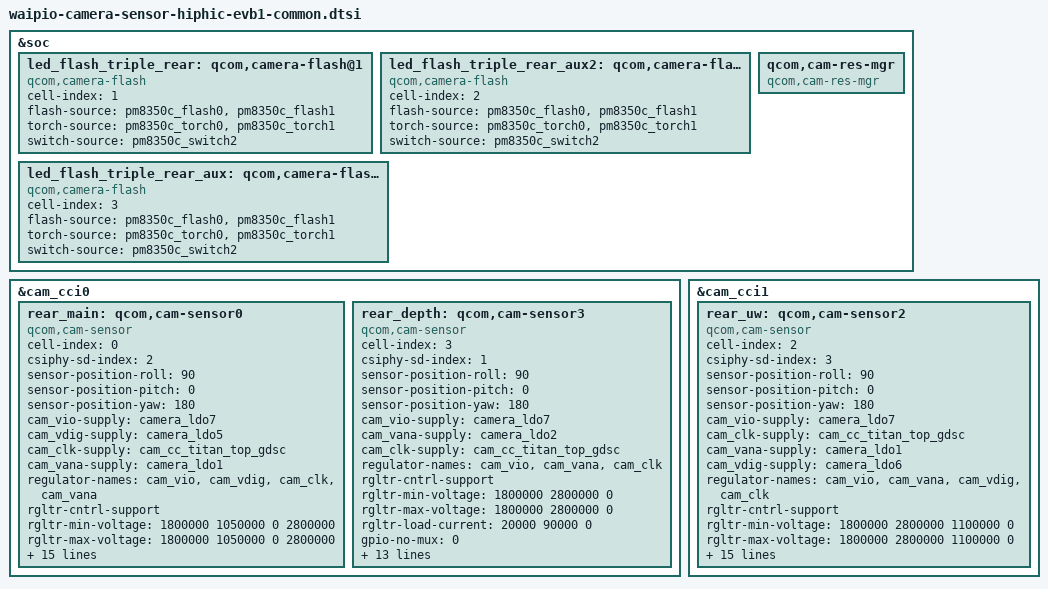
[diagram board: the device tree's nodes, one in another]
/*
   This base is original from "waipio-camera-sensor-mtp.dtsi"
*/
#include <dt-bindings/clock/qcom,camcc-waipio.h>

&soc {
	led_flash_triple_rear: qcom,camera-flash@1 {
		cell-index = <1>;
		compatible = "qcom,camera-flash";
		flash-source = <&pm8350c_flash0 &pm8350c_flash1>;
		torch-source = <&pm8350c_torch0 &pm8350c_torch1>;
		switch-source = <&pm8350c_switch2>;
		status = "ok";
	};

	led_flash_triple_rear_aux2: qcom,camera-flash@2 {
		cell-index = <2>;
		compatible = "qcom,camera-flash";
		flash-source = <&pm8350c_flash0 &pm8350c_flash1>;
		torch-source = <&pm8350c_torch0 &pm8350c_torch1>;
		switch-source = <&pm8350c_switch2>;
		status = "ok";
	};

	led_flash_triple_rear_aux: qcom,camera-flash@3 {
		cell-index = <3>;
		compatible = "qcom,camera-flash";
		flash-source = <&pm8350c_flash0 &pm8350c_flash1>;
		torch-source = <&pm8350c_torch0 &pm8350c_torch1>;
		switch-source = <&pm8350c_switch2>;
		status = "ok";
	};

	qcom,cam-res-mgr {
		compatible = "qcom,cam-res-mgr";
		status = "ok";
	};
};

&cam_cci0 {

	rear_main: qcom,cam-sensor0 {
		cell-index = <0>;
		compatible = "qcom,cam-sensor";
		csiphy-sd-index = <2>;
		sensor-position-roll = <90>;
		sensor-position-pitch = <0>;
		sensor-position-yaw = <180>;
		cam_vio-supply = <&camera_ldo7>;
		cam_vdig-supply = <&camera_ldo5>;
		cam_clk-supply = <&cam_cc_titan_top_gdsc>;
		cam_vana-supply = <&camera_ldo1>;
		regulator-names = "cam_vio", "cam_vdig",
			"cam_clk", "cam_vana";
		rgltr-cntrl-support;
		rgltr-min-voltage = <1800000 1050000 0 2800000>;
		rgltr-max-voltage = <1800000 1050000 0 2800000>;
		rgltr-load-current = <155000 680000 0 50000>;
		gpio-no-mux = <0>;
		pinctrl-names = "cam_default", "cam_suspend";
		pinctrl-0 = <&cam_sensor_mclk2_active
			&cam_sensor_active_rst2>;
		pinctrl-1 = <&cam_sensor_mclk2_suspend
			&cam_sensor_suspend_rst2>;
		gpios = <&tlmm 102 0>,
			<&tlmm 117 0>;
		gpio-reset = <1>;
		gpio-req-tbl-num = <0 1>;
		gpio-req-tbl-flags = <1 0>;
		gpio-req-tbl-label = "CAMIF_MCLK2",
					"CAM_RESET2";
		cci-master = <0>;
		clocks = <&clock_camcc CAM_CC_MCLK2_CLK>;
		clock-names = "cam_clk";
		clock-cntl-level = "nominal";
		clock-rates = <24000000>;
		status = "ok";
	};

	rear_depth: qcom,cam-sensor3 {
		cell-index = <3>;
		compatible = "qcom,cam-sensor";
		csiphy-sd-index = <1>;
		sensor-position-roll = <90>;
		sensor-position-pitch = <0>;
		sensor-position-yaw = <180>;
		cam_vio-supply = <&camera_ldo7>;
		cam_vana-supply = <&camera_ldo2>;
		cam_clk-supply = <&cam_cc_titan_top_gdsc>;
		regulator-names = "cam_vio", "cam_vana", "cam_clk";
		rgltr-cntrl-support;
		rgltr-min-voltage = <1800000 2800000 0>;
		rgltr-max-voltage = <1800000 2800000 0>;
		rgltr-load-current = <20000 90000 0>;
		gpio-no-mux = <0>;
		pinctrl-names = "cam_default", "cam_suspend";
		pinctrl-0 = <&cam_sensor_mclk1_active
				 &cam_sensor_active_rst1>;
		pinctrl-1 = <&cam_sensor_mclk1_suspend
				 &cam_sensor_suspend_rst1>;
		gpios = <&tlmm 101 0>,
			<&tlmm 24 0>;
		gpio-reset = <1>;
		gpio-req-tbl-num = <0 1>;
		gpio-req-tbl-flags = <1 0>;
		gpio-req-tbl-label = "CAMIF_MCLK1",
					"CAM_RESET1";
		cci-master = <1>;
		clocks = <&clock_camcc CAM_CC_MCLK1_CLK>;
		clock-names = "cam_clk";
		clock-cntl-level = "nominal";
		clock-rates = <24000000>;
		status = "ok";
	};
};

&cam_cci1 {
	rear_uw: qcom,cam-sensor2 {
		cell-index = <2>;
		compatible = "qcom,cam-sensor";
		csiphy-sd-index = <3>;
		sensor-position-roll = <90>;
		sensor-position-pitch = <0>;
		sensor-position-yaw = <180>;
		cam_vio-supply = <&camera_ldo7>;
		cam_clk-supply = <&cam_cc_titan_top_gdsc>;
		cam_vana-supply = <&camera_ldo1>;
		cam_vdig-supply = <&camera_ldo6>;
		regulator-names = "cam_vio", "cam_vana",
			"cam_vdig", "cam_clk";
		rgltr-cntrl-support;
		rgltr-min-voltage = <1800000 2800000 1100000 0>;
		rgltr-max-voltage = <1800000 2800000 1100000 0>;
		rgltr-load-current = <128000 128000 50000 0>;
		gpio-no-mux = <0>;
		pinctrl-names = "cam_default", "cam_suspend";
		pinctrl-0 = <&cam_sensor_mclk3_active
			&cam_sensor_active_rst3>;
		pinctrl-1 = <&cam_sensor_mclk3_suspend
			&cam_sensor_suspend_rst3>;
		gpios = <&tlmm 103 0>,
			<&tlmm 120 0>;
		gpio-reset = <1>;
		gpio-req-tbl-num = <0 1>;
		gpio-req-tbl-flags = <1 0>;
		gpio-req-tbl-label = "CAMIF_MCLK3",
			"CAM_RESET3";
		cci-master = <0>;
		clocks = <&clock_camcc CAM_CC_MCLK3_CLK>;
		clock-names = "cam_clk";
		clock-cntl-level = "nominal";
		clock-rates = <24000000>;
		status = "ok";
	};
};
